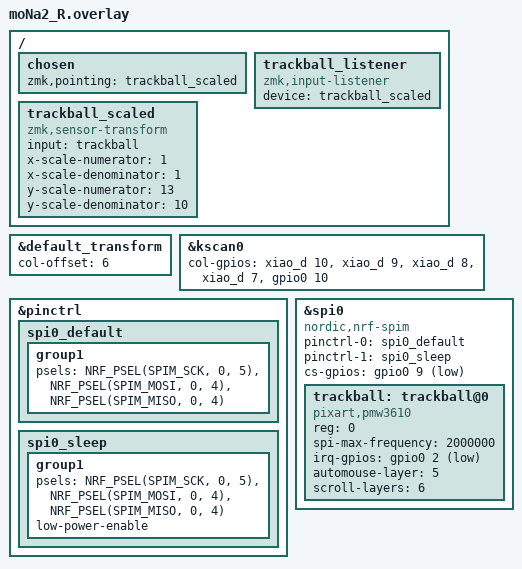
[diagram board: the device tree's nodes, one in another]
#include <dt-bindings/zmk/matrix_transform.h> // ★ 追加
#include "moNa2.dtsi"

&default_transform {
    col-offset = <6>;
};

&kscan0 {
        col-gpios
            = <&xiao_d 10 GPIO_ACTIVE_HIGH>
            , <&xiao_d 9 GPIO_ACTIVE_HIGH> 
            , <&xiao_d 8 GPIO_ACTIVE_HIGH> 
            , <&xiao_d 7 GPIO_ACTIVE_HIGH> 
            , <&gpio0 10 GPIO_ACTIVE_HIGH>
            ;
};

/ {
    // ★★★★★★★★★★★★★★★★★★★★★★★★★★★★
    // ★ これがエラーを解決する重要な追加部分です ★
    // ★★★★★★★★★★★★★★★★★★★★★★★★★★★★
    chosen {
        // ZMKに対して、最終的なポインティングデバイスとして
        // trackball_scaled を使用することを宣言します。
        zmk,pointing = <&trackball_scaled>;
    };

    // sensor-transform を使うためのリスナー
    trackball_listener {
        compatible = "zmk,input-listener";
        device = <&trackball_scaled>;
    };

    // 軸ごとの倍率を設定する transform ノード
    trackball_scaled: trackball_scaled {
        compatible = "zmk,sensor-transform";
        input = <&trackball>; // 入力元は trackball センサー
        
        // 横方向(X軸)の倍率を 1/1 = 1倍に設定
        x-scale-numerator = <1>;
        x-scale-denominator = <1>;

        // 縦方向(Y軸)の倍率を 13/10 = 1.3倍に設定
        y-scale-numerator = <13>;
        y-scale-denominator = <10>;
    };
};

&pinctrl {
    spi0_default: spi0_default {
        group1 {
            psels = <NRF_PSEL(SPIM_SCK, 0, 5)>,
                    <NRF_PSEL(SPIM_MOSI, 0, 4)>,
                    <NRF_PSEL(SPIM_MISO, 0, 4)>;
        };
    };

    spi0_sleep: spi0_sleep {
        group1 {
            psels = <NRF_PSEL(SPIM_SCK, 0, 5)>,
                    <NRF_PSEL(SPIM_MOSI, 0, 4)>,
                    <NRF_PSEL(SPIM_MISO, 0, 4)>;
            low-power-enable;
        };
    };
};

&spi0 {
    status = "okay";
    compatible = "nordic,nrf-spim";
    pinctrl-0 = <&spi0_default>;
    pinctrl-1 = <&spi0_sleep>;
    pinctrl-names = "default", "sleep";
    cs-gpios = <&gpio0 9 GPIO_ACTIVE_LOW>;

    trackball: trackball@0 {
        status = "okay";
        compatible = "pixart,pmw3610";
        reg = <0>;
        spi-max-frequency = <2000000>;
        irq-gpios = <&gpio0 2 (GPIO_ACTIVE_LOW | GPIO_PULL_UP)>;
        automouse-layer = <5>;
        scroll-layers = <6>;
    };
};
